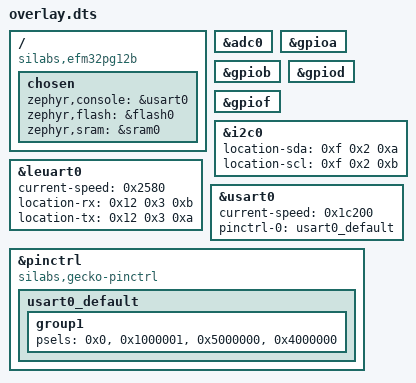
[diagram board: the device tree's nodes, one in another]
/ {
	compatible = "silabs,efm32pg12b", "silabs,efm32pg_stk3402a";
	chosen {
		zephyr,console = &usart0;
		zephyr,flash = &flash0;
		zephyr,sram = &sram0;
	};
};
&adc0{
	status = "okay";
};
&gpioa{
	status = "okay";
};
&gpiob{
	status = "okay";
};
&gpiod{
	status = "okay";
};
&gpiof{
	status = "okay";
};
&i2c0{
	status = "okay";
	location-sda = < 0xf 0x2 0xa >;
	location-scl = < 0xf 0x2 0xb >;
};
&leuart0{
	status = "okay";
	current-speed = < 0x2580 >;
	location-rx = < 0x12 0x3 0xb >;
	location-tx = < 0x12 0x3 0xa >;
};
&usart0{
	status = "okay";
	current-speed = < 0x1c200 >;
	pinctrl-0 = < &usart0_default >;
	pinctrl-names = "default";
};
&pinctrl{
	compatible = "silabs,gecko-pinctrl";
	usart0_default: usart0_default {
		group1 {
			psels = < 0x0 >, < 0x1000001 >, < 0x5000000 >, < 0x4000000 >;
		};
	};
};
